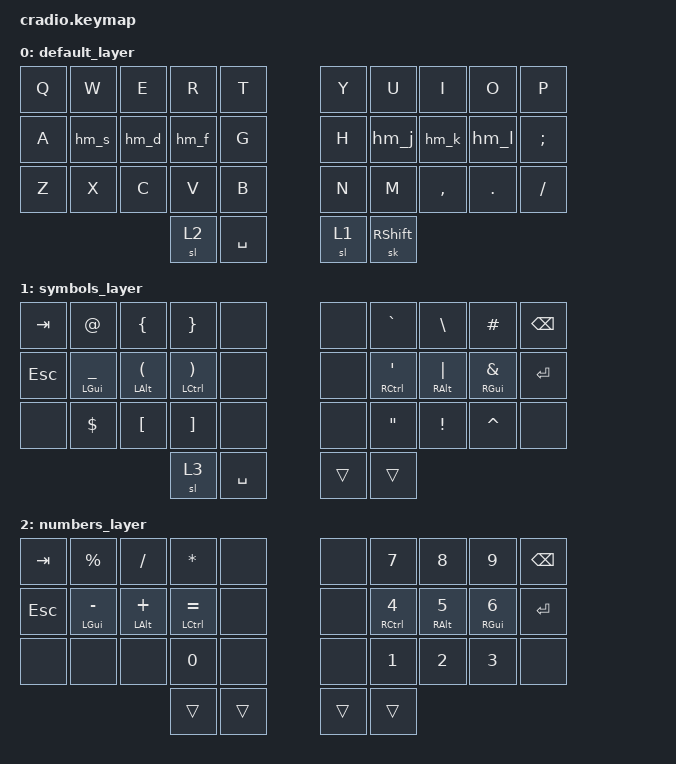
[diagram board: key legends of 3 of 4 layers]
// Copyright (c) 2022 The ZMK Contributors
// SPDX-License-Identifier: MIT

#include <behaviors.dtsi>
#include <dt-bindings/zmk/keys.h>
#include <dt-bindings/zmk/bt.h>

&sk {
    quick-release;
};

/ {
    behaviors {
        hm: homerow_mod {
            compatible = "zmk,behavior-hold-tap";
            label = "HOMEROW_MOD";
            #binding-cells = <2>;
            tapping-term-ms = <200>;
            quick-tap-ms = <150>;
            flavor = "tap-preferred";
            bindings = <&kp>, <&kp>;
        };
          
        hm_d: homerow_mod_d {
            compatible = "zmk,behavior-mod-morph";
            label = "HOMEROW_MOD_D";
            #binding-cells = <0>;
            bindings = <&hm LALT D>, <&kp D>;
            mods = <(MOD_RCTL|MOD_RALT|MOD_RGUI)>;
            keep-mods = <(MOD_RCTL|MOD_RALT|MOD_RGUI)>;
        };

        hm_s: homerow_mod_s {
            compatible = "zmk,behavior-mod-morph";
            label = "HOMEROW_MOD_S";
            #binding-cells = <0>;
            bindings = <&hm LGUI S>, <&kp S>;
            mods = <(MOD_RCTL|MOD_RALT|MOD_RGUI)>;
            keep-mods = <(MOD_RCTL|MOD_RALT|MOD_RGUI)>;
        };
          
        hm_f: homerow_mod_f {
            compatible = "zmk,behavior-mod-morph";
            label = "HOMEROW_MOD_F";
            #binding-cells = <0>;
            bindings = <&hm LCTRL F>, <&kp F>;
            mods = <(MOD_RCTL|MOD_RALT|MOD_RGUI)>;
            keep-mods = <(MOD_RCTL|MOD_RALT|MOD_RGUI)>;
        };
          
        hm_j: homerow_mod_j {
            compatible = "zmk,behavior-mod-morph";
            label = "HOMEROW_MOD_J";
            #binding-cells = <0>;
            bindings = <&hm RCTRL J>, <&kp J>;
            mods = <(MOD_LGUI|MOD_LALT|MOD_LCTL)>;
            keep-mods = <(MOD_LGUI|MOD_LALT|MOD_LCTL)>;
        };
          
        hm_k: homerow_mod_k {
            compatible = "zmk,behavior-mod-morph";
            label = "HOMEROW_MOD_K";
            #binding-cells = <0>;
            bindings = <&hm RALT K>, <&kp K>;
            mods = <(MOD_LGUI|MOD_LALT|MOD_LCTL)>;
            keep-mods = <(MOD_LGUI|MOD_LALT|MOD_LCTL)>;
        };
          
        hm_l: homerow_mod_l {
            compatible = "zmk,behavior-mod-morph";
            label = "HOMEROW_MOD_L";
            #binding-cells = <0>;
            bindings = <&hm RGUI L>, <&kp L>;
            mods = <(MOD_LGUI|MOD_LALT|MOD_LCTL)>;
            keep-mods = <(MOD_LGUI|MOD_LALT|MOD_LCTL)>;
        };

        td_reset: tap_dance_reset {
            compatible = "zmk,behavior-tap-dance";
            label = "TAP_DANCE_RESET";
            #binding-cells = <0>;
            tapping-term-ms = <200>;
            bindings = <&none>, <&none>, <&sys_reset>;
        };

        td_bootloader: tap_dance_bootloader {
            compatible = "zmk,behavior-tap-dance";
            label = "TAP_DANCE_BOOTLOADER";
            #binding-cells = <0>;
            tapping-term-ms = <200>;
            bindings = <&none>, <&none>, <&bootloader>;
        };

        td_bt_clear: tap_dance_bluetooth_clear {
            compatible = "zmk,behavior-tap-dance";
            label = "TAP_DANCE_BLUETOOTH_CLEAR";
            #binding-cells = <0>;
            tapping-term-ms = <200>;
            bindings = <&none>, <&none>, <&bt BT_CLR>;
        };
    };

    keymap {
        compatible = "zmk,keymap";
        default_layer {
            bindings = <
        //╭─────────────────┬─────────────────┬─────────────────┬─────────────────┬─────────────────╮   ╭─────────────────┬─────────────────┬─────────────────┬─────────────────┬─────────────────╮
        //│  Q              │  W              │  E              │  R              │  T              │   │  Y              │  U              │  I              │  O              │  P              │
            &kp Q             &kp W             &kp E             &kp R             &kp T                 &kp Y             &kp U             &kp I             &kp O             &kp P
        //├─────────────────┼─────────────────┼─────────────────┼─────────────────┼─────────────────┤   ├─────────────────┼─────────────────┼─────────────────┼─────────────────┼─────────────────┤
        //│  A              │  S              │  D              │  F              │  G              │   │  H              │  J              │  K              │  L              │  ; :            │
            &kp A             &hm_s             &hm_d             &hm_f             &kp G                 &kp H             &hm_j             &hm_k             &hm_l             &kp SEMI
        //├─────────────────┼─────────────────┼─────────────────┼─────────────────┼─────────────────┤   ├─────────────────┼─────────────────┼─────────────────┼─────────────────┼─────────────────┤
        //│  Z              │  X              │  C              │  V              │  B              │   │  N              │  M              │  , <            │  . >            │  / ?            │
            &kp Z             &kp X             &kp C             &kp V             &kp B                 &kp N             &kp M             &kp COMMA         &kp DOT           &kp FSLH
        //╰─────────────────┴─────────────────┴─────────────────┼─────────────────┼─────────────────┤   ├─────────────────┼─────────────────┼─────────────────┴─────────────────┴─────────────────╯
        //                                                      │  LAYER 2        │  SPACE          │   │  LAYER 1        │  SHIFT          │
                                                                  &sl 2             &kp SPACE             &sl 1             &sk RSHFT
        //                                                      ╰─────────────────┴─────────────────╯   ╰─────────────────┴─────────────────╯
            >;
        };

        symbols_layer {
            bindings = <
        //╭─────────────────┬─────────────────┬─────────────────┬─────────────────┬─────────────────╮   ╭─────────────────┬─────────────────┬─────────────────┬─────────────────┬─────────────────╮
        //│  TAB            │  @              │  {              │  }              │                 │   │                 │  ` ~            │  \              │  #              │  BSPC           │
            &kp TAB           &kp AT            &kp LBRC          &kp RBRC          &none                 &none             &kp GRAVE         &kp BSLH          &kp HASH          &kp BSPC
        //├─────────────────┼─────────────────┼─────────────────┼─────────────────┼─────────────────┤   ├─────────────────┼─────────────────┼─────────────────┼─────────────────┼─────────────────┤
        //│  ESCAPE         │  _              │  (              │  )              │                 │   │                 │  '              │  |              │  &              │  ENTER          │
            &kp ESC           &hm LGUI UNDER    &hm LALT LPAR     &hm LCTRL RPAR    &none                 &none             &hm RCTRL SQT     &hm RALT PIPE     &hm RGUI AMPS     &kp ENTER
        //├─────────────────┼─────────────────┼─────────────────┼─────────────────┼─────────────────┤   ├─────────────────┼─────────────────┼─────────────────┼─────────────────┼─────────────────┤
        //│                 │  $              │  [              │  ]              │                 │   │                 │  "              │  !              │  ^              │                 │
            &none             &kp DLLR          &kp LBKT          &kp RBKT          &none                 &none             &kp DQT           &kp EXCL          &kp CARET         &none
        //╰─────────────────┴─────────────────┴─────────────────┼─────────────────┼─────────────────┤   ├─────────────────┼─────────────────┼─────────────────┴─────────────────┴─────────────────╯
        //                                                      │  LAYER 3        │  SPACE          │   │  TRANSPARENT    │  TRANSPARENT    │
                                                                  &sl 3             &kp SPACE             &trans            &trans
        //                                                      ╰─────────────────┴─────────────────╯   ╰─────────────────┴─────────────────╯
            >;
        };

        numbers_layer {
            bindings = <
        //╭─────────────────┬─────────────────┬─────────────────┬─────────────────┬─────────────────╮   ╭─────────────────┬─────────────────┬─────────────────┬─────────────────┬─────────────────╮
        //│  TAB            │  %              │  /              │  *              │                 │   │                 │  7              │  8              │  9              │  BSPC           │
            &kp TAB           &kp PRCNT         &kp FSLH          &kp ASTRK         &none                 &none             &kp N7            &kp N8            &kp N9            &kp BSPC
        //├─────────────────┼─────────────────┼─────────────────┼─────────────────┼─────────────────┤   ├─────────────────┼─────────────────┼─────────────────┼─────────────────┼─────────────────┤
        //│  ESCAPE         │  -              │  +              │  =              │                 │   │                 │  4              │  5              │  6              │  ENTER          │
            &kp ESC           &hm LGUI MINUS    &hm LALT PLUS     &hm LCTRL EQUAL   &none                 &none             &hm RCTRL N4      &hm RALT N5       &hm RGUI N6       &kp ENTER
        //├─────────────────┼─────────────────┼─────────────────┼─────────────────┼─────────────────┤   ├─────────────────┼─────────────────┼─────────────────┼─────────────────┼─────────────────┤
        //│                 │                 │                 │  0              │                 │   │                 │  1              │  2              │  3              │                 │
            &none             &none             &none             &kp N0            &none                 &none             &kp N1            &kp N2            &kp N3            &none
        //╰─────────────────┴─────────────────┴─────────────────┼─────────────────┼─────────────────┤   ├─────────────────┼─────────────────┼─────────────────┴─────────────────┴─────────────────╯
        //                                                      │  TRANSPARENT    │  TRANSPARENT    │   │  TRANSPARENT    │  TRANSPARENT    │
                                                                  &trans            &trans                &trans            &trans
        //                                                      ╰─────────────────┴─────────────────╯   ╰─────────────────┴─────────────────╯
            >;
        };

        tri_layer {
            bindings = <
        //╭─────────────────┬─────────────────┬─────────────────┬─────────────────┬─────────────────╮   ╭─────────────────┬─────────────────┬─────────────────┬─────────────────┬─────────────────╮
        //│  TAB            │                 │                 │                 │  BOOTLOADER     │   │  HOME           │  PG DOWN        │  PG UP          │  END            │  BSPC           │
            &kp TAB           &none             &none             &none             &td_bootloader        &kp HOME          &kp PG_DN         &kp PG_UP         &kp END           &kp BSPC
        //├─────────────────┼─────────────────┼─────────────────┼─────────────────┼─────────────────┤   ├─────────────────┼─────────────────┼─────────────────┼─────────────────┼─────────────────┤
        //│  ESCAPE         │                 │                 │                 │                 │   │  LEFT           │  DOWN           │  UP             │  RIGHT          │  ENTER          │
            &kp ESC           &hm LGUI &none    &hm LALT &none    &hm LCTRL &none   &none                 &kp LEFT          &kp DOWN          &kp UP            &kp RIGHT         &kp ENTER
        //├─────────────────┼─────────────────┼─────────────────┼─────────────────┼─────────────────┤   ├─────────────────┼─────────────────┼─────────────────┼─────────────────┼─────────────────┤
        //│                 │                 │                 │                 │  RESET          │   │  BT CLEAR       │                 │                 │                 │                 │
            &none             &none             &none             &none             &td_reset             &td_bt_clear      &none             &none             &none             &none
        //╰─────────────────┴─────────────────┴─────────────────┼─────────────────┼─────────────────┤   ├─────────────────┼─────────────────┼─────────────────┴─────────────────┴─────────────────╯
        //                                                      │  TRANSPARENT    │  TRANSPARENT    │   │  TRANSPARENT    │  TRANSPARENT    │
                                                                  &trans            &trans                &trans            &trans
        //                                                      ╰─────────────────┴─────────────────╯   ╰─────────────────┴─────────────────╯
            >;
        };
    };
};
